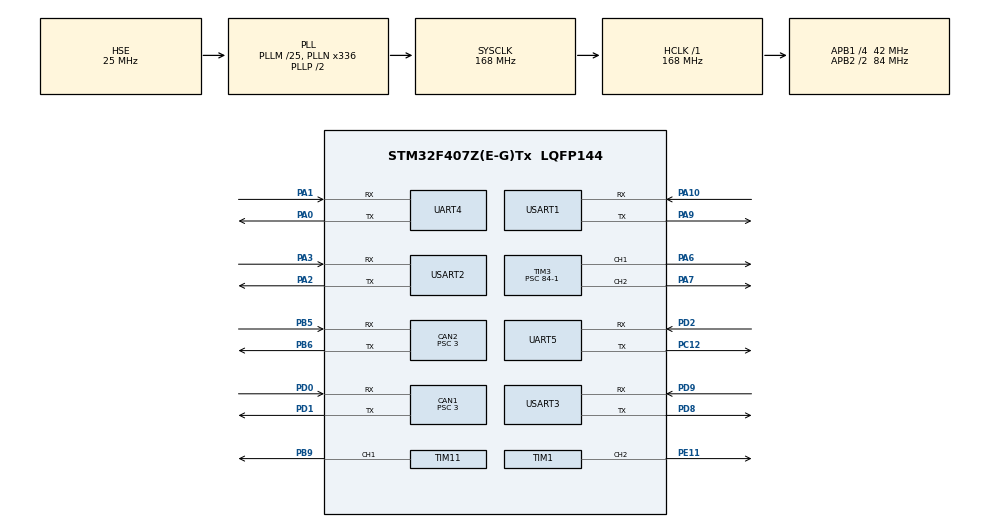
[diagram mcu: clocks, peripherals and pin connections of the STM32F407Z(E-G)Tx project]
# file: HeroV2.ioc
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CAN1.ABOM=ENABLE
CAN1.AWUM=ENABLE
CAN1.BS1=CAN_BS1_9TQ
CAN1.BS2=CAN_BS2_4TQ
CAN1.CalculateBaudRate=1000000
CAN1.CalculateTimeBit=1000
CAN1.CalculateTimeQuantum=71.42857142857143
CAN1.NART=ENABLE
CAN1.Prescaler=3
CAN1.TXFP=ENABLE
CAN2.ABOM=ENABLE
CAN2.AWUM=ENABLE
CAN2.BS1=CAN_BS1_9TQ
CAN2.BS2=CAN_BS2_4TQ
CAN2.CalculateBaudRate=1000000
CAN2.CalculateTimeBit=1000
CAN2.CalculateTimeQuantum=71.42857142857143
CAN2.NART=ENABLE
CAN2.Prescaler=3
CAN2.TXFP=ENABLE
Dma.Request0=USART1_RX
Dma.Request1=USART1_TX
Dma.Request2=USART2_RX
Dma.Request3=USART3_RX
Dma.Request4=UART4_RX
Dma.Request5=UART5_RX
Dma.Request6=UART5_TX
Dma.Request7=UART4_TX
Dma.Request8=USART3_TX
Dma.UART4_RX.4.Direction=DMA_PERIPH_TO_MEMORY
Dma.UART4_RX.4.FIFOMode=DMA_FIFOMODE_DISABLE
Dma.UART4_RX.4.Instance=DMA1_Stream2
Dma.UART4_RX.4.MemDataAlignment=DMA_MDATAALIGN_BYTE
Dma.UART4_RX.4.MemInc=DMA_MINC_ENABLE
Dma.UART4_RX.4.Mode=DMA_CIRCULAR
Dma.UART4_RX.4.PeriphDataAlignment=DMA_PDATAALIGN_BYTE
Dma.UART4_RX.4.PeriphInc=DMA_PINC_DISABLE
Dma.UART4_RX.4.Priority=DMA_PRIORITY_VERY_HIGH
Dma.UART4_TX.7.Direction=DMA_MEMORY_TO_PERIPH
Dma.UART4_TX.7.FIFOMode=DMA_FIFOMODE_DISABLE
Dma.UART4_TX.7.Instance=DMA1_Stream4
Dma.UART4_TX.7.MemDataAlignment=DMA_MDATAALIGN_BYTE
Dma.UART4_TX.7.MemInc=DMA_MINC_ENABLE
Dma.UART4_TX.7.Mode=DMA_NORMAL
Dma.UART4_TX.7.PeriphDataAlignment=DMA_PDATAALIGN_BYTE
Dma.UART4_TX.7.PeriphInc=DMA_PINC_DISABLE
Dma.UART4_TX.7.Priority=DMA_PRIORITY_VERY_HIGH
Dma.UART5_RX.5.Direction=DMA_PERIPH_TO_MEMORY
Dma.UART5_RX.5.FIFOMode=DMA_FIFOMODE_DISABLE
Dma.UART5_RX.5.Instance=DMA1_Stream0
Dma.UART5_RX.5.MemDataAlignment=DMA_MDATAALIGN_BYTE
Dma.UART5_RX.5.MemInc=DMA_MINC_ENABLE
Dma.UART5_RX.5.Mode=DMA_CIRCULAR
Dma.UART5_RX.5.PeriphDataAlignment=DMA_PDATAALIGN_BYTE
Dma.UART5_RX.5.PeriphInc=DMA_PINC_DISABLE
Dma.UART5_RX.5.Priority=DMA_PRIORITY_VERY_HIGH
Dma.UART5_TX.6.Direction=DMA_MEMORY_TO_PERIPH
Dma.UART5_TX.6.FIFOMode=DMA_FIFOMODE_DISABLE
Dma.UART5_TX.6.Instance=DMA1_Stream7
Dma.UART5_TX.6.MemDataAlignment=DMA_MDATAALIGN_BYTE
Dma.UART5_TX.6.MemInc=DMA_MINC_ENABLE
Dma.UART5_TX.6.Mode=DMA_NORMAL
Dma.UART5_TX.6.PeriphDataAlignment=DMA_PDATAALIGN_BYTE
Dma.UART5_TX.6.PeriphInc=DMA_PINC_DISABLE
Dma.UART5_TX.6.Priority=DMA_PRIORITY_VERY_HIGH
Dma.USART1_RX.0.Direction=DMA_PERIPH_TO_MEMORY
Dma.USART1_RX.0.FIFOMode=DMA_FIFOMODE_DISABLE
Dma.USART1_RX.0.Instance=DMA2_Stream2
Dma.USART1_RX.0.MemDataAlignment=DMA_MDATAALIGN_BYTE
Dma.USART1_RX.0.MemInc=DMA_MINC_ENABLE
Dma.USART1_RX.0.Mode=DMA_CIRCULAR
Dma.USART1_RX.0.PeriphDataAlignment=DMA_PDATAALIGN_BYTE
Dma.USART1_RX.0.PeriphInc=DMA_PINC_DISABLE
Dma.USART1_RX.0.Priority=DMA_PRIORITY_VERY_HIGH
Dma.USART1_TX.1.Direction=DMA_MEMORY_TO_PERIPH
Dma.USART1_TX.1.FIFOMode=DMA_FIFOMODE_DISABLE
Dma.USART1_TX.1.Instance=DMA2_Stream7
Dma.USART1_TX.1.MemDataAlignment=DMA_MDATAALIGN_BYTE
Dma.USART1_TX.1.MemInc=DMA_MINC_ENABLE
Dma.USART1_TX.1.Mode=DMA_NORMAL
Dma.USART1_TX.1.PeriphDataAlignment=DMA_PDATAALIGN_BYTE
Dma.USART1_TX.1.PeriphInc=DMA_PINC_DISABLE
Dma.USART1_TX.1.Priority=DMA_PRIORITY_VERY_HIGH
Dma.USART2_RX.2.Direction=DMA_PERIPH_TO_MEMORY
Dma.USART2_RX.2.FIFOMode=DMA_FIFOMODE_DISABLE
Dma.USART2_RX.2.Instance=DMA1_Stream5
Dma.USART2_RX.2.MemDataAlignment=DMA_MDATAALIGN_BYTE
Dma.USART2_RX.2.MemInc=DMA_MINC_ENABLE
Dma.USART2_RX.2.Mode=DMA_CIRCULAR
Dma.USART2_RX.2.PeriphDataAlignment=DMA_PDATAALIGN_BYTE
Dma.USART2_RX.2.PeriphInc=DMA_PINC_DISABLE
Dma.USART2_RX.2.Priority=DMA_PRIORITY_LOW
Dma.USART3_RX.3.Direction=DMA_PERIPH_TO_MEMORY
Dma.USART3_RX.3.FIFOMode=DMA_FIFOMODE_DISABLE
Dma.USART3_RX.3.Instance=DMA1_Stream1
Dma.USART3_RX.3.MemDataAlignment=DMA_MDATAALIGN_BYTE
Dma.USART3_RX.3.MemInc=DMA_MINC_ENABLE
Dma.USART3_RX.3.Mode=DMA_CIRCULAR
Dma.USART3_RX.3.PeriphDataAlignment=DMA_PDATAALIGN_BYTE
Dma.USART3_RX.3.PeriphInc=DMA_PINC_DISABLE
Dma.USART3_RX.3.Priority=DMA_PRIORITY_HIGH
Dma.USART3_TX.8.Direction=DMA_MEMORY_TO_PERIPH
Dma.USART3_TX.8.FIFOMode=DMA_FIFOMODE_DISABLE
Dma.USART3_TX.8.Instance=DMA1_Stream3
Dma.USART3_TX.8.MemDataAlignment=DMA_MDATAALIGN_BYTE
Dma.USART3_TX.8.MemInc=DMA_MINC_ENABLE
Dma.USART3_TX.8.Mode=DMA_CIRCULAR
Dma.USART3_TX.8.PeriphDataAlignment=DMA_PDATAALIGN_BYTE
Dma.USART3_TX.8.PeriphInc=DMA_PINC_DISABLE
Dma.USART3_TX.8.Priority=DMA_PRIORITY_HIGH
FREERTOS.Tasks01=defaultTask,0,128,StartDefaultTask,Default,NULL,Dynamic,NULL,NULL;ControlTask,2,1024,Control_Task,As weak,NULL,Dynamic,NULL,NULL
Mcu.Family=STM32F4
Mcu.Name=STM32F407Z(E-G)Tx
Mcu.Package=LQFP144
NVIC.CAN1_RX0_IRQn=true\:5\:0\:false\:false\:true\:true\:true\:true
NVIC.CAN2_RX0_IRQn=true\:5\:0\:false\:false\:true\:true\:true\:true
NVIC.DMA1_Stream0_IRQn=true\:5\:0\:false\:false\:true\:true\:false\:true
NVIC.DMA1_Stream1_IRQn=true\:5\:0\:false\:false\:true\:true\:false\:true
NVIC.DMA1_Stream2_IRQn=true\:5\:0\:false\:false\:true\:true\:false\:true
NVIC.DMA1_Stream3_IRQn=true\:5\:0\:false\:false\:true\:true\:false\:true
NVIC.DMA1_Stream4_IRQn=true\:5\:0\:false\:false\:true\:true\:false\:true
NVIC.DMA1_Stream5_IRQn=true\:5\:0\:false\:false\:true\:true\:false\:true
NVIC.DMA1_Stream7_IRQn=true\:5\:0\:false\:false\:true\:true\:false\:true
NVIC.DMA2_Stream2_IRQn=true\:5\:0\:false\:false\:true\:true\:false\:true
NVIC.DMA2_Stream7_IRQn=true\:5\:0\:false\:false\:true\:true\:false\:true
NVIC.PriorityGroup=NVIC_PRIORITYGROUP_4
NVIC.TIM2_IRQn=true\:15\:0\:false\:false\:true\:false\:false\:true
NVIC.TimeBase=TIM2_IRQn
NVIC.TimeBaseIP=TIM2
NVIC.UART4_IRQn=true\:5\:0\:false\:false\:true\:true\:true\:true
NVIC.UART5_IRQn=true\:5\:0\:false\:false\:true\:true\:true\:true
NVIC.USART1_IRQn=true\:5\:0\:false\:false\:true\:true\:true\:true
NVIC.USART2_IRQn=true\:5\:0\:false\:false\:true\:true\:true\:true
NVIC.USART3_IRQn=true\:5\:0\:false\:false\:true\:true\:true\:true
PA0-WKUP.Mode=Asynchronous
PA0-WKUP.Signal=UART4_TX
PA1.Mode=Asynchronous
PA1.Signal=UART4_RX
PA10.Mode=Asynchronous
PA10.Signal=USART1_RX
PA13.Mode=Serial_Wire
PA13.Signal=SYS_JTMS-SWDIO
PA14.Mode=Serial_Wire
PA14.Signal=SYS_JTCK-SWCLK
PA2.Mode=Asynchronous
PA2.Signal=USART2_TX
PA3.Mode=Asynchronous
PA3.Signal=USART2_RX
PA6.Signal=S_TIM3_CH1
PA7.Signal=S_TIM3_CH2
PA9.Mode=Asynchronous
PA9.Signal=USART1_TX
PB5.Mode=CAN_Activate
PB5.Signal=CAN2_RX
PB6.Mode=CAN_Activate
PB6.Signal=CAN2_TX
PB9.Signal=S_TIM11_CH1
PC12.Mode=Asynchronous
PC12.Signal=UART5_TX
PD0.Mode=CAN_Activate
PD0.Signal=CAN1_RX
PD1.Mode=CAN_Activate
PD1.Signal=CAN1_TX
PD2.Mode=Asynchronous
PD2.Signal=UART5_RX
PD8.Mode=Asynchronous
PD8.Signal=USART3_TX
PD9.Mode=Asynchronous
PD9.Signal=USART3_RX
PE11.Signal=S_TIM1_CH2
PH0-OSC_IN.Mode=HSE-External-Oscillator
PH0-OSC_IN.Signal=RCC_OSC_IN
PH1-OSC_OUT.Mode=HSE-External-Oscillator
PH1-OSC_OUT.Signal=RCC_OSC_OUT
ProjectManager.HeapSize=0x200
ProjectManager.StackSize=0x400
ProjectManager.TargetToolchain=MDK-ARM V5.32
RCC.48MHZClocksFreq_Value=84000000
RCC.AHBFreq_Value=168000000
RCC.APB1CLKDivider=RCC_HCLK_DIV4
RCC.APB1Freq_Value=42000000
RCC.APB1TimFreq_Value=84000000
RCC.APB2CLKDivider=RCC_HCLK_DIV2
RCC.APB2Freq_Value=84000000
RCC.APB2TimFreq_Value=168000000
RCC.CortexFreq_Value=168000000
RCC.HCLKFreq_Value=168000000
RCC.HSE_VALUE=25000000
RCC.HSI_VALUE=16000000
RCC.LSE_VALUE=32768
RCC.PLLM=25
RCC.PLLN=336
RCC.PLLSourceVirtual=RCC_PLLSOURCE_HSE
RCC.SYSCLKFreq_VALUE=168000000
RCC.SYSCLKSource=RCC_SYSCLKSOURCE_PLLCLK
RCC.VCOOutputFreq_Value=336000000
SH.S_TIM11_CH1.0=TIM11_CH1,PWM Generation1 CH1
SH.S_TIM1_CH2.0=TIM1_CH2,PWM Generation2 CH2
SH.S_TIM3_CH1.0=TIM3_CH1,PWM Generation1 CH1
SH.S_TIM3_CH2.0=TIM3_CH2,PWM Generation2 CH2
TIM1.Channel-PWM\ Generation2\ CH2=TIM_CHANNEL_2
TIM1.Period=1000-1
TIM1.Prescaler=3360-1
TIM11.Channel=TIM_CHANNEL_1
TIM11.Period=500
TIM11.Prescaler=168-1
TIM3.Channel-PWM\ Generation1\ CH1=TIM_CHANNEL_1
TIM3.Channel-PWM\ Generation2\ CH2=TIM_CHANNEL_2
TIM3.Period=2500-1
TIM3.Prescaler=84-1
UART4.VirtualMode=Asynchronous
UART5.VirtualMode=Asynchronous
USART1.VirtualMode=VM_ASYNC
USART2.VirtualMode=VM_ASYNC
USART3.VirtualMode=VM_ASYNC
VP_FREERTOS_VS_CMSIS_V1.Mode=CMSIS_V1
VP_IWDG_VS_IWDG.Mode=IWDG_Activate
VP_SYS_VS_tim2.Mode=TIM2
VP_TIM11_VS_ClockSourceINT.Mode=Enable_Timer
VP_TIM1_VS_ClockSourceINT.Mode=Internal
VP_TIM3_VS_ClockSourceINT.Mode=Internal
board=custom

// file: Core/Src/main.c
/* USER CODE BEGIN Header */
/**
  ******************************************************************************
  * @file           : main.c
  * @brief          : Main program body
  ******************************************************************************
  * @attention
  *
  * Copyright (c) 2023 STMicroelectronics.
  * All rights reserved.
  *
  * This software is licensed under terms that can be found in the LICENSE file
  * in the root directory of this software component.
  * If no LICENSE file comes with this software, it is provided AS-IS.
  *
  ******************************************************************************
  */
/* USER CODE END Header */
#include "main.h"
#include "cmsis_os.h"
#include "can.h"
#include "dma.h"
#include "iwdg.h"
#include "tim.h"
#include "usart.h"
#include "gpio.h"

/* USER CODE BEGIN Includes */
#include "drive.h"
/* USER CODE END Includes */

void SystemClock_Config(void);
void MX_FREERTOS_Init(void);

int main(void)
{

  /* MCU Configuration--------------------------------------------------------*/

  /* Reset of all peripherals, Initializes the Flash interface and the Systick. */
  HAL_Init();

  /* Configure the system clock */
  SystemClock_Config();

  /* Initialize all configured peripherals */
  MX_GPIO_Init();
  MX_DMA_Init();
  MX_CAN1_Init();
  MX_CAN2_Init();
  MX_IWDG_Init();
  MX_USART1_UART_Init();
  MX_USART2_UART_Init();
  MX_USART3_UART_Init();
  MX_UART4_Init();
  MX_UART5_Init();
  MX_TIM1_Init();
  MX_TIM3_Init();
  MX_TIM11_Init();
  /* USER CODE BEGIN 2 */
  driver_init();
  /* USER CODE END 2 */

  /* Call init function for freertos objects (in freertos.c) */
  MX_FREERTOS_Init();
  /* Start scheduler */
  osKernelStart();

  /* We should never get here as control is now taken by the scheduler */
  /* Infinite loop */
  while (1)
  {

  }
}

void SystemClock_Config(void)
{
  RCC_OscInitTypeDef RCC_OscInitStruct = {0};
  RCC_ClkInitTypeDef RCC_ClkInitStruct = {0};

  /** Configure the main internal regulator output voltage
  */
  __HAL_RCC_PWR_CLK_ENABLE();
  __HAL_PWR_VOLTAGESCALING_CONFIG(PWR_REGULATOR_VOLTAGE_SCALE1);
  /** Initializes the RCC Oscillators according to the specified parameters
  * in the RCC_OscInitTypeDef structure.
  */
  RCC_OscInitStruct.OscillatorType = RCC_OSCILLATORTYPE_LSI|RCC_OSCILLATORTYPE_HSE;
  RCC_OscInitStruct.HSEState = RCC_HSE_ON;
  RCC_OscInitStruct.LSIState = RCC_LSI_ON;
  RCC_OscInitStruct.PLL.PLLState = RCC_PLL_ON;
  RCC_OscInitStruct.PLL.PLLSource = RCC_PLLSOURCE_HSE;
  RCC_OscInitStruct.PLL.PLLM = 25;
  RCC_OscInitStruct.PLL.PLLN = 336;
  RCC_OscInitStruct.PLL.PLLP = RCC_PLLP_DIV2;
  RCC_OscInitStruct.PLL.PLLQ = 4;
  if (HAL_RCC_OscConfig(&RCC_OscInitStruct) != HAL_OK)
  {
    Error_Handler();
  }
  /** Initializes the CPU, AHB and APB buses clocks
  */
  RCC_ClkInitStruct.ClockType = RCC_CLOCKTYPE_HCLK|RCC_CLOCKTYPE_SYSCLK
                              |RCC_CLOCKTYPE_PCLK1|RCC_CLOCKTYPE_PCLK2;
  RCC_ClkInitStruct.SYSCLKSource = RCC_SYSCLKSOURCE_PLLCLK;
  RCC_ClkInitStruct.AHBCLKDivider = RCC_SYSCLK_DIV1;
  RCC_ClkInitStruct.APB1CLKDivider = RCC_HCLK_DIV4;
  RCC_ClkInitStruct.APB2CLKDivider = RCC_HCLK_DIV2;

  if (HAL_RCC_ClockConfig(&RCC_ClkInitStruct, FLASH_LATENCY_5) != HAL_OK)
  {
    Error_Handler();
  }
}

void HAL_TIM_PeriodElapsedCallback(TIM_HandleTypeDef *htim)
{
  if (htim->Instance == TIM2) {
    HAL_IncTick();
  }
}

void Error_Handler(void)
{
  __disable_irq();
  while (1)
  {
  }
}

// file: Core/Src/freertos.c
/* USER CODE BEGIN Header */
/**
  ******************************************************************************
  * File Name          : freertos.c
  * Description        : Code for freertos applications
  ******************************************************************************
  * @attention
  *
  * Copyright (c) 2023 STMicroelectronics.
  * All rights reserved.
  *
  * This software is licensed under terms that can be found in the LICENSE file
  * in the root directory of this software component.
  * If no LICENSE file comes with this software, it is provided AS-IS.
  *
  ******************************************************************************
  */
/* USER CODE END Header */

#include "FreeRTOS.h"
#include "task.h"
#include "main.h"
#include "cmsis_os.h"

osThreadId defaultTaskHandle;
osThreadId ControlTaskHandle;

void StartDefaultTask(void const * argument);
void Control_Task(void const * argument);

void MX_FREERTOS_Init(void); /* (MISRA C 2004 rule 8.1) */

/* GetIdleTaskMemory prototype (linked to static allocation support) */
void vApplicationGetIdleTaskMemory( StaticTask_t **ppxIdleTaskTCBBuffer, StackType_t **ppxIdleTaskStackBuffer, uint32_t *pulIdleTaskStackSize );

/* USER CODE BEGIN GET_IDLE_TASK_MEMORY */
static StaticTask_t xIdleTaskTCBBuffer;
static StackType_t xIdleStack[configMINIMAL_STACK_SIZE];

void vApplicationGetIdleTaskMemory( StaticTask_t **ppxIdleTaskTCBBuffer, StackType_t **ppxIdleTaskStackBuffer, uint32_t *pulIdleTaskStackSize )
{
  *ppxIdleTaskTCBBuffer = &xIdleTaskTCBBuffer;
  *ppxIdleTaskStackBuffer = &xIdleStack[0];
  *pulIdleTaskStackSize = configMINIMAL_STACK_SIZE;
  /* place for user code */
}
/* USER CODE END GET_IDLE_TASK_MEMORY */

void MX_FREERTOS_Init(void) {

  /* Create the thread(s) */
  /* definition and creation of defaultTask */
  osThreadDef(defaultTask, StartDefaultTask, osPriorityNormal, 0, 128);
  defaultTaskHandle = osThreadCreate(osThread(defaultTask), NULL);

  /* definition and creation of ControlTask */
  osThreadDef(ControlTask, Control_Task, osPriorityHigh, 0, 1024);
  ControlTaskHandle = osThreadCreate(osThread(ControlTask), NULL);

}

void StartDefaultTask(void const * argument)
{
  for(;;)
  {
    osDelay(1);
  }
}

__weak void Control_Task(void const * argument)
{
  for(;;)
  {
    osDelay(1);
  }
}
